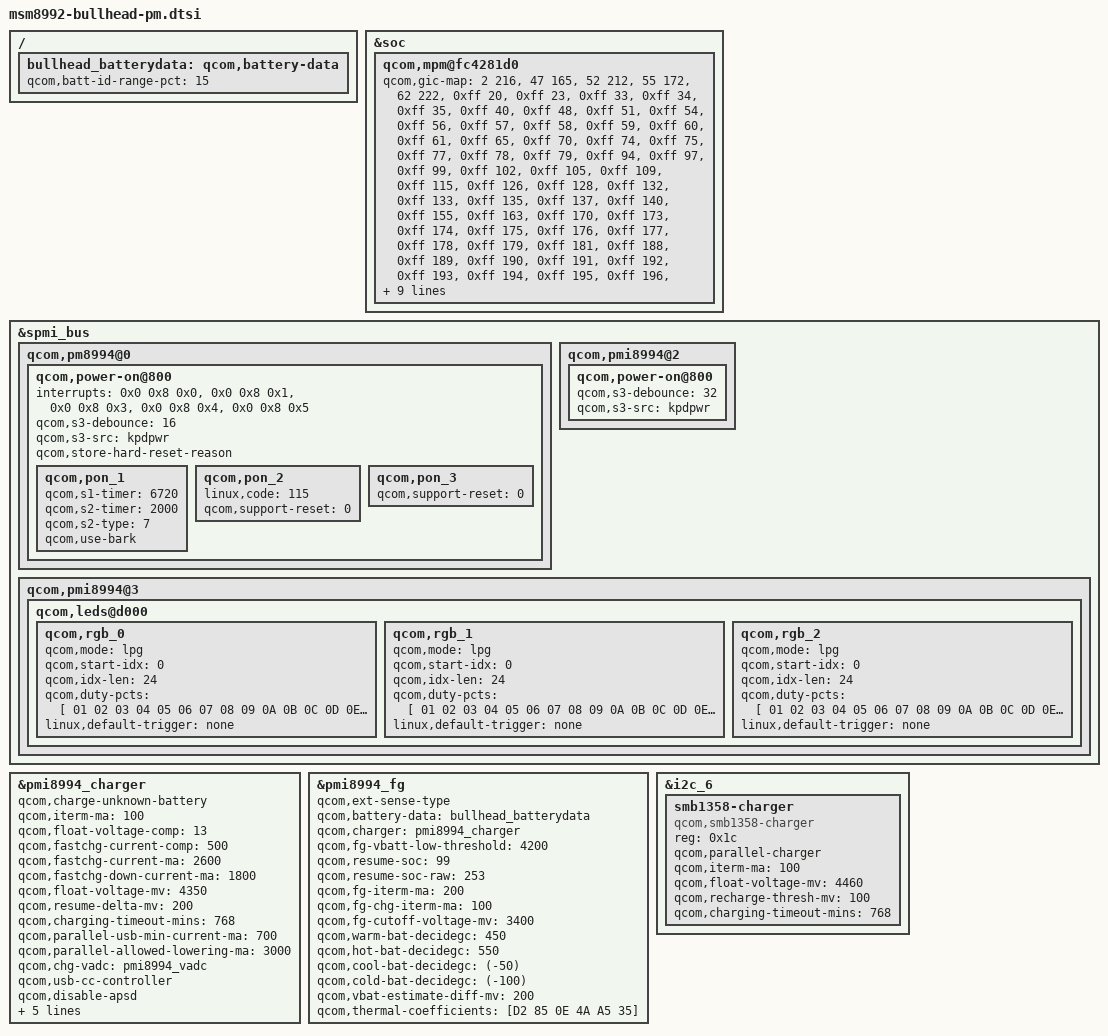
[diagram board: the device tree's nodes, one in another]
/* Copyright (c) 2015, LGE Inc. All rights reserved.
 * Copyright (c) 2014, The Linux Foundation. All rights reserved.
 *
 * This program is free software; you can redistribute it and/or modify
 * it under the terms of the GNU General Public License version 2 and
 * only version 2 as published by the Free Software Foundation.
 *
 * This program is distributed in the hope that it will be useful,
 * but WITHOUT ANY WARRANTY; without even the implied warranty of
 * MERCHANTABILITY or FITNESS FOR A PARTICULAR PURPOSE.  See the
 * GNU General Public License for more details.
 */

&soc {
	qcom,mpm@fc4281d0 {
		qcom,gic-map = <2 216>, /* tsens_upper_lower_int */
			<47 165>,   /* usb30_hs_phy_irq */
			<52 212>,   /* lfps_rxterm_irq for pwr_event_irq */
			<55 172>,   /* usb1_hs_async_wakeup_irq */
			<62 222>,   /* ee0_krait_hlos_spmi_periph_irq */
			<0xff 20>,  /* arch_timer */
			<0xff 23>,  /* ARM64 Single-Bit Error PMU IRQ */
			<0xff 33>,  /* APCC_qgicL2PerfMonIrptReq */
			<0xff 34>,  /* APCC_qgicL2ErrorIrptReq */
			<0xff 35>,  /* WDT_barkInt */
			<0xff 40>,  /* qtimer_phy_irq */
			<0xff 48>,  /* cpr */
			<0xff 51>,  /* cpr*/
			<0xff 54>,  /* CCI error IRQ */
			<0xff 56>,  /* modem_watchdog */
			<0xff 57>,  /* mss_to_apps_irq(0) */
			<0xff 58>,  /* mss_to_apps_irq(1) */
			<0xff 59>,  /* mss_to_apps_irq(2) */
			<0xff 60>,  /* mss_to_apps_irq(3) */
			<0xff 61>,  /* mss_a2_bam_irq */
			<0xff 65>,  /* kgsl-3d0 */
			<0xff 70>,  /* iommu_pmon_nonsecure_irq */
			<0xff 74>,  /* osmmu_CIrpt[1] */
			<0xff 75>,  /* osmmu_CIrpt[0] */
			<0xff 77>,  /* osmmu_CIrpt[0] */
			<0xff 78>,  /* osmmu_CIrpt[0] */
			<0xff 79>,  /* osmmu_CIrpt[0] */
			<0xff 94>,  /* osmmu_CIrpt[0] */
			<0xff 97>,  /* iommu_nonsecure_irq */
			<0xff 99>,  /* msm_iommu_pmon_nonsecure_irq */
			<0xff 102>, /* osmmu_CIrpt[1] */
			<0xff 105>, /* iommu_pmon_nonsecure_irq */
			<0xff 109>, /* ocmem_dm_nonsec_irq */
			<0xff 115>, /* MDSS */
			<0xff 126>, /* bam_irq[0] */
			<0xff 128>, /* i2c-msm-v2-irq */
			<0xff 132>, /* i2c-msm-v2-irq */
			<0xff 133>, /* f9963000.spi */
			<0xff 135>, /* i2c-msm-v2-irq */
			<0xff 137>, /* i2c-msm-v2-irq */
			<0xff 140>, /* msm_serial_hsl0 */
			<0xff 155>, /* sdcc_irq[0] */
			<0xff 163>, /* usb30_ee1_irq */
			<0xff 170>, /* sdcc_pwr_cmd_irq */
			<0xff 173>, /* o_wcss_apss_smd_hi */
			<0xff 174>, /* o_wcss_apss_smd_med */
			<0xff 175>, /* o_wcss_apss_smd_low */
			<0xff 176>, /* o_wcss_apss_smsm_irq */
			<0xff 177>, /* o_wcss_apss_wlan_data_xfer_done */
			<0xff 178>, /* o_wcss_apss_wlan_rx_data_avail */
			<0xff 179>, /* o_wcss_apss_asic_intr */
			<0xff 181>, /* wcnss watchdog */
			<0xff 188>, /* lpass_irq_out_apcs(0) */
			<0xff 189>, /* lpass_irq_out_apcs(1) */
			<0xff 190>, /* lpass_irq_out_apcs(2) */
			<0xff 191>, /* lpass_irq_out_apcs(3) */
			<0xff 192>, /* lpass_irq_out_apcs(4) */
			<0xff 193>, /* lpass_irq_out_apcs(5) */
			<0xff 194>, /* lpass_irq_out_apcs(6) */
			<0xff 195>, /* lpass_irq_out_apcs(7) */
			<0xff 196>, /* lpass_irq_out_apcs(8) */
			<0xff 197>, /* lpass_irq_out_apcs(9) */
			<0xff 198>, /* coresight-tmc-etr interrupt */
			<0xff 200>, /* rpm_ipc(4) */
			<0xff 201>, /* rpm_ipc(5) */
			<0xff 202>, /* rpm_ipc(6) */
			<0xff 203>, /* rpm_ipc(7) */
			<0xff 204>, /* rpm_ipc(24) */
			<0xff 205>, /* rpm_ipc(25) */
			<0xff 206>, /* rpm_ipc(26) */
			<0xff 207>, /* rpm_ipc(27) */
			<0xff 211>, /* usb_dwc3_otg */
			<0xff 215>, /* fc388000.qcom,cpu-bwmon */
			<0xff 224>, /* spdm_bw_hyp */
			<0xff 240>, /* summary_irq_kpss */
			<0xff 261>, /* msm_iommu_global_cfg_irq */
			<0xff 263>, /* msm_iommu_global_client_irq */
			<0xff 268>, /* bam_irq[1] */
			<0xff 270>, /* bam_irq[0] */
			<0xff 271>, /* bam_irq[0] */
			<0xff 272>, /* msm_iommu_secure_irq */
			<0xff 273>, /* msm_iommu_nonsecure_irq */
			<0xff 275>, /* int_msi */
			<0xff 276>, /* wlan_pci */
			<0xff 283>, /* int_pls_err */
			<0xff 284>, /* int_aer_legacy */
			<0xff 286>, /* int_aer_legacy */
			<0xff 298>, /* msm_iommu_nonsecure_irq */
			<0xff 302>, /* coresight-tmc-etr */
			<0xff 332>, /* sps */
			<0xff 333>, /* ipa */
			<0xff 360>, /* ARM64 primary DBE IRQ */
			<0xff 361>, /* ARM64 secondary DBE IRQ */
			<0xff 362>, /* ARM64 primary ext IRQ */
			<0xff 363>, /* ARM64 secondary ext IRQ */
			<0xff 364>; /* lmh_interrupt */
	};
};

&spmi_bus {
	qcom,pm8994@0 {
		qcom,power-on@800 {
			interrupts = <0x0 0x8 0x0>,
					<0x0 0x8 0x1>,
					<0x0 0x8 0x3>,
					<0x0 0x8 0x4>,
					<0x0 0x8 0x5>;
			interrupt-names = "kpdpwr", "resin", "kpdpwr-bark",
					"resin-bark", "kpdpwr-resin-bark";
			qcom,s3-debounce = <16>;
			qcom,s3-src = "kpdpwr";
			qcom,store-hard-reset-reason;
			qcom,pon_1 { /* KPD_PWR_N reset */
				status = "ok";
				qcom,s1-timer = <6720>;
				qcom,s2-timer = <2000>;
				qcom,s2-type = <7>;
				qcom,use-bark;
			};
			qcom,pon_2 { /* RESIN_N reset   */
				status = "ok";
				linux,code = <115>;
				qcom,support-reset = <0>;
			};
			qcom,pon_3 { /* KPD_PWR_N AND RESIN_N reset */
				status = "ok";
				qcom,support-reset = <0>;
			};
		};
	};

	qcom,pmi8994@2 {
		qcom,power-on@800 {
			qcom,s3-debounce = <32>;
			qcom,s3-src = "kpdpwr";
		};
	};
};

&pmi8994_charger {
	status = "ok";
	qcom,charge-unknown-battery;
	qcom,iterm-ma = <100>;
	qcom,float-voltage-comp = <13>; /* 4.1V */
	qcom,fastchg-current-comp = <500>; /* 500mA */
	qcom,fastchg-current-ma = <2600>;
	qcom,fastchg-down-current-ma = <1800>;
	qcom,float-voltage-mv = <4350>;
	qcom,resume-delta-mv = <200>;
	qcom,charging-timeout-mins = <768>;
	qcom,parallel-usb-min-current-ma = <700>;
	qcom,parallel-allowed-lowering-ma = <3000>;
	qcom,chg-vadc = <&pmi8994_vadc>;
	/delete-property/ qcom,dc-psy-type;
	qcom,usb-cc-controller;
	qcom,disable-apsd;
	qcom,disable-hvdcp;
	qcom,customized-jeita;
	/delete-property/ qcom,thermal-mitigation;
	qcom,ibat-thermal-mitigation = <1400 1200 600 1200 300 1200 100 600 0 0>;
	qcom,battery-data = <&bullhead_batterydata>;
};

/{
	bullhead_batterydata: qcom,battery-data {
		qcom,batt-id-range-pct = <15>;
		#include "lge_blt19_byd_2700mAh_2022234_PMI8994GUI2165.dtsi"
		#include "lge_blt19_tocad_2700mAh_2022227_PMI8994GUI2165.dtsi"
	};
};

&pmi8994_fg {
	status = "ok";
	qcom,ext-sense-type;
	qcom,battery-data = <&bullhead_batterydata>;
	qcom,charger = <&pmi8994_charger>;
	qcom,fg-vbatt-low-threshold = <4200>;
	qcom,resume-soc = <99>;
	qcom,resume-soc-raw = <253>;
	qcom,fg-iterm-ma = <200>;
	qcom,fg-chg-iterm-ma = <100>;
	qcom,fg-cutoff-voltage-mv = <3400>;
	qcom,warm-bat-decidegc = <450>;
	qcom,hot-bat-decidegc = <550>;
	qcom,cool-bat-decidegc = <(-50)>;
	qcom,cold-bat-decidegc = <(-100)>;
	qcom,vbat-estimate-diff-mv = <200>;
	qcom,thermal-coefficients = [D2 85 0E 4A A5 35];
};

&i2c_6 {
	status = "ok";
	smb1358-charger {
		status = "ok";
		compatible = "qcom,smb1358-charger";
		reg = <0x1c>;
		qcom,parallel-charger;
		qcom,iterm-ma = <100>;
		qcom,float-voltage-mv = <4460>;
		qcom,recharge-thresh-mv = <100>;
		qcom,charging-timeout-mins = <768>;
	};
};

&spmi_bus {
	qcom,pmi8994@3 {
		qcom,leds@d000 {
			qcom,rgb_0 {
				qcom,mode = "lpg";
				qcom,start-idx = <0>;
				qcom,idx-len = <24>;
				qcom,duty-pcts = [
					01 02 03 04 05 06 07 08
					09 0A 0B 0C 0D 0E 0F 10
					11 12 13 14 15 16 17 18];
				linux,default-trigger = "none";
			};

			qcom,rgb_1 {
				qcom,mode = "lpg";
				qcom,start-idx = <0>;
				qcom,idx-len = <24>;
				qcom,duty-pcts = [
					01 02 03 04 05 06 07 08
					09 0A 0B 0C 0D 0E 0F 10
					11 12 13 14 15 16 17 18];
				linux,default-trigger = "none";
			};

			qcom,rgb_2 {
				qcom,mode = "lpg";
				qcom,start-idx = <0>;
				qcom,idx-len = <24>;
				qcom,duty-pcts = [
					01 02 03 04 05 06 07 08
					09 0A 0B 0C 0D 0E 0F 10
					11 12 13 14 15 16 17 18];
				linux,default-trigger = "none";
			};
		};
	};
};
